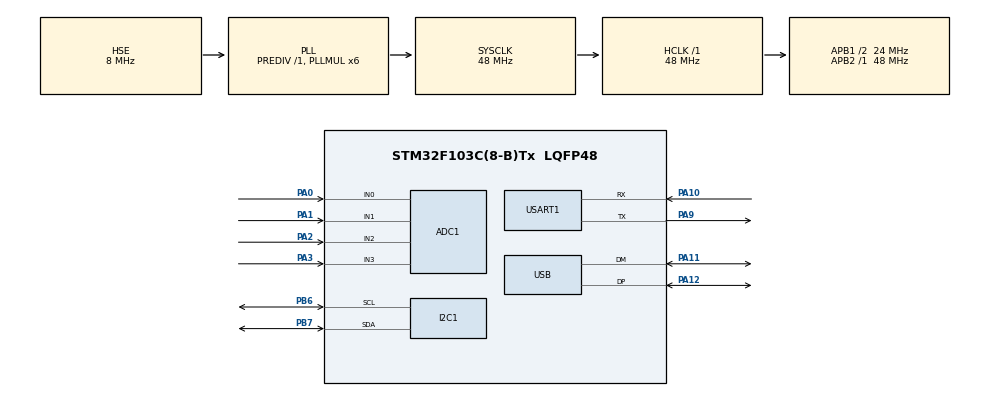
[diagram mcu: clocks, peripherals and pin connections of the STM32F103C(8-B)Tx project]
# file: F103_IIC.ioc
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ADC1.Channel-0\#ChannelRegularConversion=ADC_CHANNEL_0
ADC1.Channel-1\#ChannelRegularConversion=ADC_CHANNEL_1
ADC1.Channel-2\#ChannelRegularConversion=ADC_CHANNEL_2
ADC1.Channel-3\#ChannelRegularConversion=ADC_CHANNEL_3
ADC1.DiscontinuousConvMode=ENABLE
ADC1.NbrOfConversion=4
ADC1.NbrOfConversionFlag=1
ADC1.Rank-0\#ChannelRegularConversion=1
ADC1.Rank-1\#ChannelRegularConversion=2
ADC1.Rank-2\#ChannelRegularConversion=3
ADC1.Rank-3\#ChannelRegularConversion=4
ADC1.SamplingTime-0\#ChannelRegularConversion=ADC_SAMPLETIME_55CYCLES_5
ADC1.SamplingTime-1\#ChannelRegularConversion=ADC_SAMPLETIME_55CYCLES_5
ADC1.SamplingTime-2\#ChannelRegularConversion=ADC_SAMPLETIME_55CYCLES_5
ADC1.SamplingTime-3\#ChannelRegularConversion=ADC_SAMPLETIME_55CYCLES_5
ADC1.master=1
Mcu.Family=STM32F1
Mcu.Name=STM32F103C(8-B)Tx
Mcu.Package=LQFP48
NVIC.PriorityGroup=NVIC_PRIORITYGROUP_4
PA0-WKUP.Signal=ADCx_IN0
PA1.Signal=ADCx_IN1
PA10.Mode=Asynchronous
PA10.Signal=USART1_RX
PA11.Mode=Device
PA11.Signal=USB_DM
PA12.Mode=Device
PA12.Signal=USB_DP
PA13.Mode=Serial_Wire
PA13.Signal=SYS_JTMS-SWDIO
PA14.Mode=Serial_Wire
PA14.Signal=SYS_JTCK-SWCLK
PA2.Signal=ADCx_IN2
PA3.Signal=ADCx_IN3
PA9.Mode=Asynchronous
PA9.Signal=USART1_TX
PB6.Mode=I2C
PB6.Signal=I2C1_SCL
PB7.Mode=I2C
PB7.Signal=I2C1_SDA
PD0-OSC_IN.Mode=HSE-External-Oscillator
PD0-OSC_IN.Signal=RCC_OSC_IN
PD1-OSC_OUT.Mode=HSE-External-Oscillator
PD1-OSC_OUT.Signal=RCC_OSC_OUT
ProjectManager.HeapSize=0x200
ProjectManager.StackSize=0x400
ProjectManager.TargetToolchain=MDK-ARM V5
RCC.ADCPresc=RCC_ADCPCLK2_DIV4
RCC.AHBFreq_Value=48000000
RCC.APB1CLKDivider=RCC_HCLK_DIV2
RCC.APB1Freq_Value=24000000
RCC.APB1TimFreq_Value=48000000
RCC.APB2Freq_Value=48000000
RCC.APB2TimFreq_Value=48000000
RCC.HCLKFreq_Value=48000000
RCC.PLLMUL=RCC_PLL_MUL6
RCC.SYSCLKFreq_VALUE=48000000
RCC.SYSCLKSource=RCC_SYSCLKSOURCE_PLLCLK
RCC.USBFreq_Value=48000000
SH.ADCx_IN0.0=ADC1_IN0,IN0
SH.ADCx_IN1.0=ADC1_IN1,IN1
SH.ADCx_IN2.0=ADC1_IN2,IN2
SH.ADCx_IN3.0=ADC1_IN3,IN3
USART1.VirtualMode=VM_ASYNC
board=custom

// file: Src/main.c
/* USER CODE BEGIN Header */
/**
  ******************************************************************************
  * @file           : main.c
  * @brief          : Main program body
  ******************************************************************************
  * @attention
  *
  * <h2><center>&copy; Copyright (c) 2020 STMicroelectronics.
  * All rights reserved.</center></h2>
  *
  * This software component is licensed by ST under BSD 3-Clause license,
  * the "License"; You may not use this file except in compliance with the
  * License. You may obtain a copy of the License at:
  *                        opensource.org/licenses/BSD-3-Clause
  *
  ******************************************************************************
  */
/* USER CODE END Header */

#include "main.h"

ADC_HandleTypeDef hadc1;

I2C_HandleTypeDef hi2c1;

UART_HandleTypeDef huart1;

PCD_HandleTypeDef hpcd_USB_FS;

void SystemClock_Config(void);
static void MX_GPIO_Init(void);
static void MX_I2C1_Init(void);
static void MX_USART1_UART_Init(void);
static void MX_USB_PCD_Init(void);
static void MX_ADC1_Init(void);

int main(void)
{

  /* MCU Configuration--------------------------------------------------------*/

  /* Reset of all peripherals, Initializes the Flash interface and the Systick. */
  HAL_Init();

  /* Configure the system clock */
  SystemClock_Config();

  /* Initialize all configured peripherals */
  MX_GPIO_Init();
  MX_I2C1_Init();
  MX_USART1_UART_Init();
  MX_USB_PCD_Init();
  MX_ADC1_Init();

  /* Infinite loop */
  /* USER CODE BEGIN WHILE */
//	scanAddr();
//	ads1015();
  while (1)
  {
    /* USER CODE END WHILE */

    /* USER CODE BEGIN 3 */
		uint32_t tickstart;
		tickstart = HAL_GetTick() + 500*2;
		while(1)
		{
			if(HAL_GetTick() > tickstart)
			{
				//ads1015();
				stm32ADC();
				break;
			}
		}
  }
  /* USER CODE END 3 */
}

void SystemClock_Config(void)
{
  RCC_OscInitTypeDef RCC_OscInitStruct = {0};
  RCC_ClkInitTypeDef RCC_ClkInitStruct = {0};
  RCC_PeriphCLKInitTypeDef PeriphClkInit = {0};

  /** Initializes the CPU, AHB and APB busses clocks
  */
  RCC_OscInitStruct.OscillatorType = RCC_OSCILLATORTYPE_HSE;
  RCC_OscInitStruct.HSEState = RCC_HSE_ON;
  RCC_OscInitStruct.HSEPredivValue = RCC_HSE_PREDIV_DIV1;
  RCC_OscInitStruct.HSIState = RCC_HSI_ON;
  RCC_OscInitStruct.PLL.PLLState = RCC_PLL_ON;
  RCC_OscInitStruct.PLL.PLLSource = RCC_PLLSOURCE_HSE;
  RCC_OscInitStruct.PLL.PLLMUL = RCC_PLL_MUL6;
  if (HAL_RCC_OscConfig(&RCC_OscInitStruct) != HAL_OK)
  {
    Error_Handler();
  }
  /** Initializes the CPU, AHB and APB busses clocks
  */
  RCC_ClkInitStruct.ClockType = RCC_CLOCKTYPE_HCLK|RCC_CLOCKTYPE_SYSCLK
                              |RCC_CLOCKTYPE_PCLK1|RCC_CLOCKTYPE_PCLK2;
  RCC_ClkInitStruct.SYSCLKSource = RCC_SYSCLKSOURCE_PLLCLK;
  RCC_ClkInitStruct.AHBCLKDivider = RCC_SYSCLK_DIV1;
  RCC_ClkInitStruct.APB1CLKDivider = RCC_HCLK_DIV2;
  RCC_ClkInitStruct.APB2CLKDivider = RCC_HCLK_DIV1;

  if (HAL_RCC_ClockConfig(&RCC_ClkInitStruct, FLASH_LATENCY_1) != HAL_OK)
  {
    Error_Handler();
  }
  PeriphClkInit.PeriphClockSelection = RCC_PERIPHCLK_ADC|RCC_PERIPHCLK_USB;
  PeriphClkInit.AdcClockSelection = RCC_ADCPCLK2_DIV4;
  PeriphClkInit.UsbClockSelection = RCC_USBCLKSOURCE_PLL;
  if (HAL_RCCEx_PeriphCLKConfig(&PeriphClkInit) != HAL_OK)
  {
    Error_Handler();
  }
}

static void MX_ADC1_Init(void)
{

  ADC_ChannelConfTypeDef sConfig = {0};

  /** Common config
  */
  hadc1.Instance = ADC1;
  hadc1.Init.ScanConvMode = ADC_SCAN_ENABLE;
  hadc1.Init.ContinuousConvMode = DISABLE;
  hadc1.Init.DiscontinuousConvMode = ENABLE;
  hadc1.Init.NbrOfDiscConversion = 1;
  hadc1.Init.ExternalTrigConv = ADC_SOFTWARE_START;
  hadc1.Init.DataAlign = ADC_DATAALIGN_RIGHT;
  hadc1.Init.NbrOfConversion = 4;
  if (HAL_ADC_Init(&hadc1) != HAL_OK)
  {
    Error_Handler();
  }
  /** Configure Regular Channel
  */
  sConfig.Channel = ADC_CHANNEL_0;
  sConfig.Rank = ADC_REGULAR_RANK_1;
  sConfig.SamplingTime = ADC_SAMPLETIME_55CYCLES_5;
  if (HAL_ADC_ConfigChannel(&hadc1, &sConfig) != HAL_OK)
  {
    Error_Handler();
  }
  /** Configure Regular Channel
  */
  sConfig.Channel = ADC_CHANNEL_1;
  sConfig.Rank = ADC_REGULAR_RANK_2;
  if (HAL_ADC_ConfigChannel(&hadc1, &sConfig) != HAL_OK)
  {
    Error_Handler();
  }
  /** Configure Regular Channel
  */
  sConfig.Channel = ADC_CHANNEL_2;
  sConfig.Rank = ADC_REGULAR_RANK_3;
  if (HAL_ADC_ConfigChannel(&hadc1, &sConfig) != HAL_OK)
  {
    Error_Handler();
  }
  /** Configure Regular Channel
  */
  sConfig.Channel = ADC_CHANNEL_3;
  sConfig.Rank = ADC_REGULAR_RANK_4;
  if (HAL_ADC_ConfigChannel(&hadc1, &sConfig) != HAL_OK)
  {
    Error_Handler();
  }

}

static void MX_I2C1_Init(void)
{

  hi2c1.Instance = I2C1;
  hi2c1.Init.ClockSpeed = 100000;
  hi2c1.Init.DutyCycle = I2C_DUTYCYCLE_2;
  hi2c1.Init.OwnAddress1 = 0;
  hi2c1.Init.AddressingMode = I2C_ADDRESSINGMODE_7BIT;
  hi2c1.Init.DualAddressMode = I2C_DUALADDRESS_DISABLE;
  hi2c1.Init.OwnAddress2 = 0;
  hi2c1.Init.GeneralCallMode = I2C_GENERALCALL_DISABLE;
  hi2c1.Init.NoStretchMode = I2C_NOSTRETCH_DISABLE;
  if (HAL_I2C_Init(&hi2c1) != HAL_OK)
  {
    Error_Handler();
  }

}

static void MX_USART1_UART_Init(void)
{

  huart1.Instance = USART1;
  huart1.Init.BaudRate = 115200;
  huart1.Init.WordLength = UART_WORDLENGTH_8B;
  huart1.Init.StopBits = UART_STOPBITS_1;
  huart1.Init.Parity = UART_PARITY_NONE;
  huart1.Init.Mode = UART_MODE_TX_RX;
  huart1.Init.HwFlowCtl = UART_HWCONTROL_NONE;
  huart1.Init.OverSampling = UART_OVERSAMPLING_16;
  if (HAL_UART_Init(&huart1) != HAL_OK)
  {
    Error_Handler();
  }

}

static void MX_USB_PCD_Init(void)
{

  hpcd_USB_FS.Instance = USB;
  hpcd_USB_FS.Init.dev_endpoints = 8;
  hpcd_USB_FS.Init.speed = PCD_SPEED_FULL;
  hpcd_USB_FS.Init.low_power_enable = DISABLE;
  hpcd_USB_FS.Init.lpm_enable = DISABLE;
  hpcd_USB_FS.Init.battery_charging_enable = DISABLE;
  if (HAL_PCD_Init(&hpcd_USB_FS) != HAL_OK)
  {
    Error_Handler();
  }

}

static void MX_GPIO_Init(void)
{

  /* GPIO Ports Clock Enable */
  __HAL_RCC_GPIOD_CLK_ENABLE();
  __HAL_RCC_GPIOA_CLK_ENABLE();
  __HAL_RCC_GPIOB_CLK_ENABLE();

}

void Error_Handler(void)
{
}

/************************ (C) COPYRIGHT STMicroelectronics *****END OF FILE****/
